VERSION ""

NS_ :

BS_:

BU_: TMS

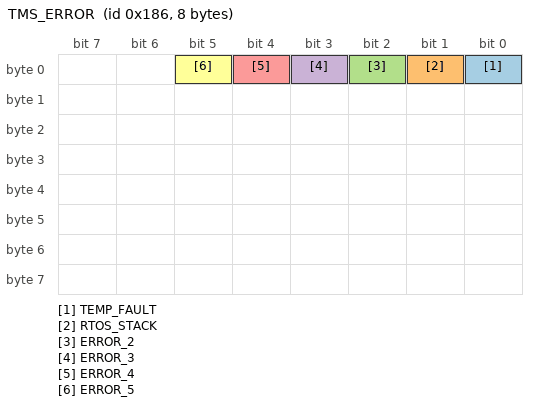
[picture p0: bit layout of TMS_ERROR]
BO_ 390 TMS_ERROR: 8 TMS
 SG_ TEMP_FAULT : 0|1@1- (1,0) [0|0] "bool" Vector_XXX
 SG_ RTOS_STACK : 1|1@1- (1,0) [0|0] "bool" Vector_XXX
 SG_ ERROR_2 : 2|1@1- (1,0) [0|0] "bool" Vector_XXX
 SG_ ERROR_3 : 3|1@1- (1,0) [0|0] "bool" Vector_XXX
 SG_ ERROR_4 : 4|1@1- (1,0) [0|0] "bool" Vector_XXX
 SG_ ERROR_5 : 5|1@1- (1,0) [0|0] "bool" Vector_XXX
